# AT32UC3C1128C device description
Architecture: AVR32_UC3; Family: AVR UC3
Registers are 32-bit, read-write, reset 0x0 unless marked. A register's access mark holds for its fields unless they carry their own. Offsets are from the block's base; [hi:lo] are bit positions; {n}, {i} and the like mark numbered series; 'fields as' and 'values as' point back to an identical list.

## IISC — Inter-IC Sound (I2S) Controller
Instances: IISC 0xffff4800
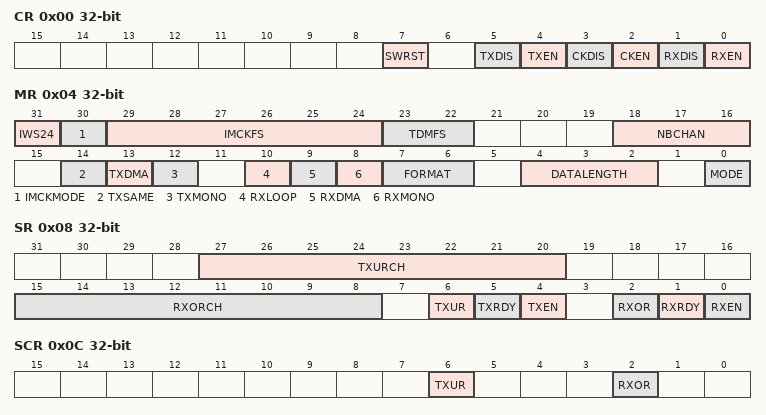
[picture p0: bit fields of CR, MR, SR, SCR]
0x00 CR wo reset not defined — Control Register
  [all] fields
    0=OFF; 1=ON
  [7] SWRST — Software Reset
  [5] TXDIS — Transmit Disable
  [4] TXEN — Transmit Enable
  [3] CKDIS — Clocks Disable
  [2] CKEN — Clocks Enable
  [1] RXDIS — Receive Disable
  [0] RXEN — Receive Enable
0x04 MR — Mode Register
  [31] IWS24 — IWS TDM Slot Width
    0=32; 1=24
  [30] IMCKMODE — Master Clock Mode
    0=NO_IMCK; 1=IMCK
  [29:24] IMCKFS — Master Clock to fs Ratio
    0=16; 1=32; 3=64; 7=128; 15=256; 23=384; 31=512; 47=768; 63=1024
  [23:22] TDMFS — TDM Frame Sync Format
    0=SLOT; 1=HALF; 2=BIT
  [18:16] NBCHAN — Number of Data Channels - 1
  [14] TXSAME — Transmit Data when Underrun
    0=ZERO; 1=SAME
  [13] TXDMA — Single or Multiple DMA Channels for Transmitter
    0=SINGLE; 1=MULTIPLE
  [12] TXMONO — Transmitter Mono
    0=STEREO; 1=MONO
  [10] RXLOOP — Loop-back Test Mode
    0=OFF; 1=ON
  [9] RXDMA — Single or Multiple DMA Channels for Receiver
    0=SINGLE; 1=MULTIPLE
  [8] RXMONO — Receiver Mono
    0=STEREO; 1=MONO
  [7:6] FORMAT — Frame Format
    0=I2S
  [4:2] DATALENGTH — Data Word Length
    0=32; 1=24; 2=20; 3=18; 4=16; 5=16C; 6=8; 7=8C
  [0] MODE — Master/Slave/Controller Mode
    0=SLAVE; 1=MASTER
0x08 SR ro — Status Register
  [27:20] TXURCH — Transmit Underrun Channels
    0=LEFT; 1=RIGHT
  [15:8] RXORCH — Receive Overrun Channels
    0=LEFT; 1=RIGHT
  [6] TXUR — Transmit Underrun
    0=NO; 1=SET
  [5] TXRDY — Transmit Ready
    0=FULL; 1=EMPTY
  [4] TXEN — Transmit Enable
    0=OFF; 1=ON
  [2] RXOR — Receive Overrun
    0=NO; 1=SET
  [1] RXRDY — Receive Ready
    0=EMPTY; 1=FULL
  [0] RXEN — Receive Enable
    0=OFF; 1=ON
0x0C SCR wo reset not defined — Status Clear Register
  [6] TXUR — Transmit Underrun
    0=NO; 1=SET
  [2] RXOR — Receive Overrun
    0=NO; 1=SET
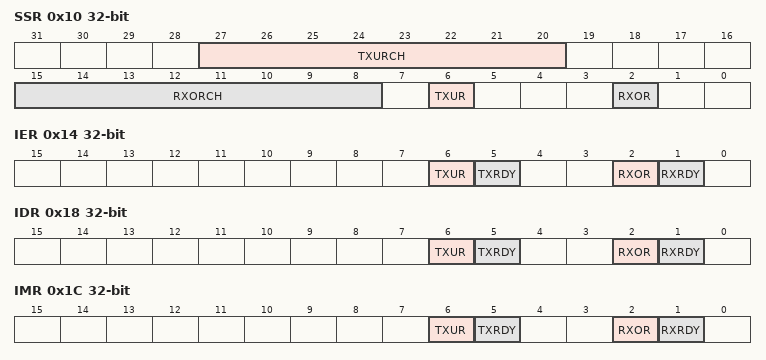
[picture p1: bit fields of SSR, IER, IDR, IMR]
0x10 SSR wo reset not defined — Status Set Register
  [27:20] TXURCH — Transmit Underrun Channels
  [15:8] RXORCH — Receive Overrun Channels
  [6] TXUR — Transmit Underrun
    0=NO; 1=SET
  [2] RXOR — Receive Overrun
    0=NO; 1=SET
0x14 IER wo reset not defined — Interrupt Enable Register
  [6] TXUR — Transmit Underrun Interrupt Enable
    0=NO; 1=SET
  [5] TXRDY — Transmit Ready Interrupt Enable
    0=FULL; 1=EMPTY
  [2] RXOR — Receive Overrun Interrupt Enable
    0=NO; 1=SET
  [1] RXRDY — Receiver Ready Interrupt Enable
    0=EMPTY; 1=FULL
0x18 IDR wo reset not defined — Interrupt Disable Register
  [6] TXUR — Transmit Underrun Interrupt Disable
    0=NO; 1=SET
  [5] TXRDY — Transmit Ready Interrupt Disable
    0=FULL; 1=EMPTY
  [2] RXOR — Receive Overrun Interrupt Disable
    0=NO; 1=SET
  [1] RXRDY — Receive Ready Interrupt Disable
    0=EMPTY; 1=FULL
0x1C IMR ro — Interrupt Mask Register
  [6] TXUR — Transmit Underrun Interrupt Mask
    0=NO; 1=SET
  [5] TXRDY — Transmit Ready Interrupt Mask
    0=FULL; 1=EMPTY
  [2] RXOR — Receive Overrun Interrupt Mask
    0=NO; 1=SET
  [1] RXRDY — Receive Ready Interrupt Mask
    0=EMPTY; 1=FULL
0x20 RHR ro — Receive Holding Register
  [31:0] RDAT — Receive Data
0x24 THR wo reset not defined — Transmit Holding Register
  [31:0] TDAT — Transmit Data
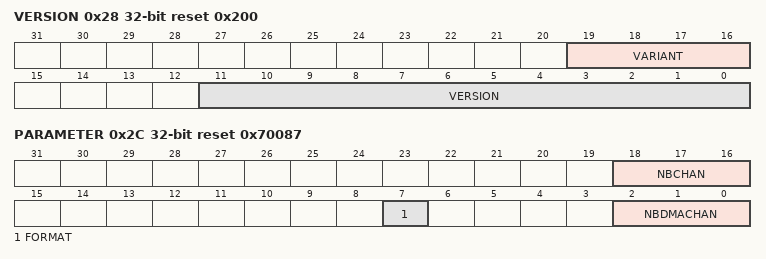
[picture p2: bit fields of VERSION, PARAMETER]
0x28 VERSION ro reset 0x200
  [19:16] VARIANT — Reserved. Value subject to change. No functionality associated.
  [11:0] VERSION — Reserved. Value subject to change. No functionality associated. This is the Atmel internal version of the macrocell.
0x2C PARAMETER ro reset 0x70087
  [18:16] NBCHAN — Maximum number of channels - 1
  [7] FORMAT — Data protocol format
    0=I2S
  [2:0] NBDMACHAN — Maximum number of DMA channels - 1

## MDMA — Memory DMA
Instances: MDMA 0xfffd1000
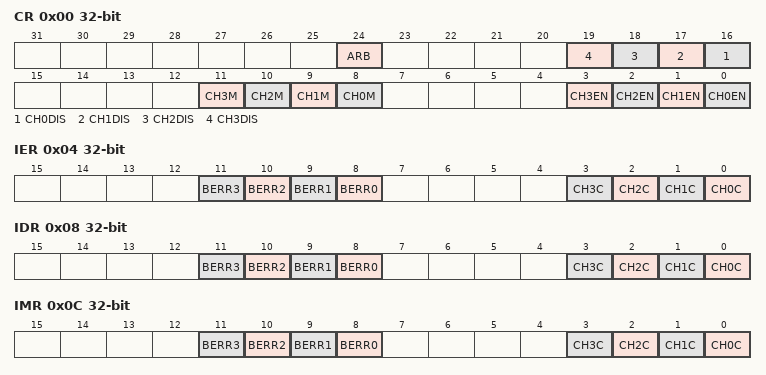
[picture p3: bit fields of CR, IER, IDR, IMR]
0x00 CR — Control Register
  [24] ARB — Arbitration Mode
  [n+16] CH{n}DIS (n=0..3) — Channel Disable
  [n+8] CH{n}M (n=0..3) — Channel Mode
  [n] CH{n}EN (n=0..3) — Channel Enable
0x04 IER wo — Interrupt Enable Register
  [n+8] BERR{n} (n=0..3) — Channel Bus Error
  [n] CH{n}C (n=0..3) — Channel Complete
0x08 IDR wo — Interrupt Disable Register
  fields as IER
0x0C IMR ro — Interrupt Mask Register
  fields as IER
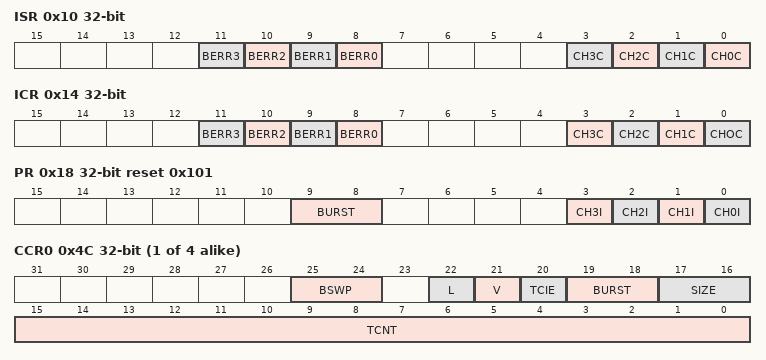
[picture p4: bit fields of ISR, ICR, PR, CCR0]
0x10 ISR ro — Interrupt Status Register
  fields as IER
0x14 ICR wo — Interrupt Clear Register
  [n+8] BERR{n} (n=0..3) — Channel Bus Error
  [3] CH3C — Channel Complete
  [2] CH2C — Channel Complete
  [1] CH1C — Channel Complete
  [0] CHOC — Channel Complete
0x18 PR ro reset 0x101 — Parameter Register
  [9:8] BURST — Maximum Burst Size
  [n] CH{n}I (n=0..3) — Channel Implemented
0x1C VR ro reset 0x101 — Version Register
  [11:0] VERSION — Version Number
{0x20+4i} DSAR{i} reset not defined (i=0..3) — Descriptor Start Address
  [31:0] DSAR — Descriptor Start Address Register
{0x40+0x10*i} CDAR{i} reset not defined (i=0..3) — Current Descriptor Address Register
  [31:0] CDAR
{0x44+0x10*i} RAR{i} reset not defined (i=0..3) — Read Address Register
  [31:0] RAR
{0x48+0x10*i} WAR{i} reset not defined (i=0..3) — Write Address register
  [31:0] WAR — Write Address Register
{0x4C+0x10*i} CCR{i} reset not defined (i=0..3) — Channel Control Register
  [25:24] BSWP — Byte Swap
  [22] L — Last Descriptor in Chain
  [21] V — Descriptor Valid
  [20] TCIE — Transfer Complete Interrupt Enable
  [19:18] BURST — Transfer Burst Size
  [17:16] SIZE — Transfer Data Size
  [15:0] TCNT — Transfer Count
